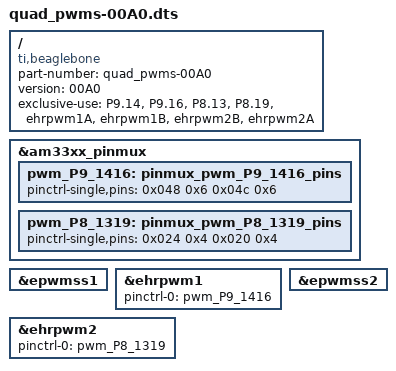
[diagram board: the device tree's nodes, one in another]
/*
 * Copyright (C) 2013 CircuitCo
 * Copyright (C) 2013 Texas Instruments
 *
 * This program is free software; you can redistribute it and/or modify
 * it under the terms of the GNU General Public License version 2 as
 * published by the Free Software Foundation.
 */
/dts-v1/;
/plugin/;

/ {
	compatible = "ti,beaglebone", "ti,beaglebone-black";

	/* identification */
	part-number = "quad_pwms-00A0";
	version = "00A0";

	/* state the resources this cape uses */
	exclusive-use =
		/* the pin header uses */
		"P9.14",		/* pwm: ehrpwm1A */
		"P9.16",		/* pwm: ehrpwm1B */
	      "P8.13",		/* pwm: ehrpwm2B */
	      "P8.19",		/* pwm: ehrpwm2A */
		/* the hardware IP uses */
		"ehrpwm1A",
		"ehrpwm1B",
		"ehrpwm2B",
		"ehrpwm2A";

	fragment@0 {
		target = <&am33xx_pinmux>;
		__overlay__ {
			pwm_P9_1416: pinmux_pwm_P9_1416_pins {
				pinctrl-single,pins = <
					0x048  0x6	/* P9_14 (ZCZ ball U14) | MODE 6 */
					0x04c  0x6	/* P9_16 (ZCZ ball T14) | MODE 6 */
                     >; 
			};

                pwm_P8_1319: pinmux_pwm_P8_1319_pins {
				pinctrl-single,pins = <
					0x024  0x4	/* P8_13 (ZCZ ball T10) | MODE 4 */
					0x020  0x4 /* P8_19 (ZCZ ball U10) | MODE 4 */
                     >; 
			};


		};
	};

     

	/* fragment@1 {
		target = <&ocp>;
		__overlay__ {
			pwm_test_P9_14 {
				compatible	= "pwm_test";
				pwms 		= <&ehrpwm1 0 500000 1>;
				pwm-names 	= "PWM_P9_14";
			    pinctrl-names	= "default";
			    pinctrl-0	= <&pwm_P9_14>;
				enabled		= <1>;
				duty		= <0>;
				status 		= "okay";
			};
		};
	};

*/
      fragment@2 {
		target = <&epwmss1>;
		__overlay__ {
			status = "okay";
		};
	};

	fragment@3 {
		target = <&ehrpwm1>;
		__overlay__ {
			pinctrl-names = "default";
			pinctrl-0 = <&pwm_P9_1416>;
			status = "okay";
		};
	};

      fragment@4 {
		target = <&epwmss2>;
		__overlay__ {
			status = "okay";
		};
	};

	fragment@5 {
		target = <&ehrpwm2>;
		__overlay__ {
			pinctrl-names = "default";
			pinctrl-0 = <&pwm_P8_1319>;
			status = "okay";
		};
	};

};
